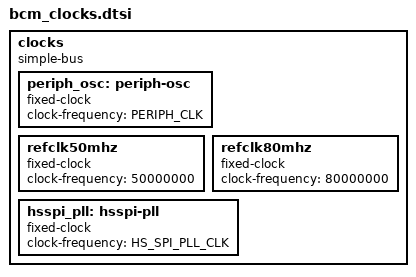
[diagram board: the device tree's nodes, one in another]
clocks: clocks {
	compatible = "simple-bus";


	periph_osc: periph-osc {
		compatible = "fixed-clock";
		#clock-cells = <0>;
		clock-frequency = <PERIPH_CLK>;

	};
	refclk50mhz: refclk50mhz {
		compatible = "fixed-clock";
		#clock-cells = <0>;
		clock-frequency = <50000000>;
	};
	refclk80mhz: refclk80mhz {
		compatible = "fixed-clock";
		#clock-cells = <0>;
		clock-frequency = <80000000>;
	};
	hsspi_pll: hsspi-pll {
		compatible = "fixed-clock";
		#clock-cells = <0>;
		clock-frequency = <HS_SPI_PLL_CLK>;

	};	
};

